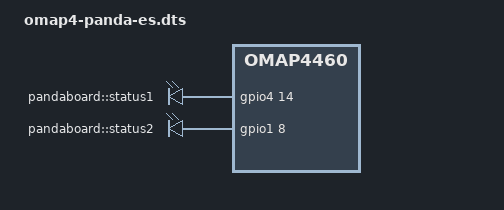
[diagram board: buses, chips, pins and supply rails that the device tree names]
/*
 * Copyright (C) 2012 Texas Instruments Incorporated - http://www.ti.com/
 *
 * This program is free software; you can redistribute it and/or modify
 * it under the terms of the GNU General Public License version 2 as
 * published by the Free Software Foundation.
 */
/dts-v1/;

/include/ "omap4460.dtsi"
/include/ "omap4-panda-common.dtsi"

&leds {
	compatible = "gpio-leds";
	heartbeat {
		label = "pandaboard::status1";
		gpios = <&gpio4 14 0>;
		linux,default-trigger = "heartbeat";
	};
	mmc {
		label = "pandaboard::status2";
		gpios = <&gpio1 8 0>;
		linux,default-trigger = "gpio";
	};
};

&led_gpio_pins {
	pinctrl-single,pins = <
		0xb6 0x3	/* gpio_110 OUTPUT | MODE 3 */
	>;
};

&omap4_pmx_wkup {
	pinctrl-names = "default";
	pinctrl-0 = <
		&led_wkgpio_pins
	>;

	led_wkgpio_pins: pinmux_leds_wkpins {
		pinctrl-single,pins = <
			0x1c 0x3	/* gpio_wk8 OUTPUT | MODE 3 */
		>;
	};
};

/* Audio routing is differnet between PandaBoard4430 and PandaBoardES */
&sound {
	ti,model = "PandaBoardES";

	/* Audio routing */
	ti,audio-routing =
		"Headset Stereophone", "HSOL",
		"Headset Stereophone", "HSOR",
		"Ext Spk", "HFL",
		"Ext Spk", "HFR",
		"Line Out", "AUXL",
		"Line Out", "AUXR",
		"AFML", "Line In",
		"AFMR", "Line In",
		"Headset Playback", "PDM_DL1",
		"Handsfree Playback", "PDM_DL2",
		"PDM_UL1", "Capture",
		"40122000.mcbsp Playback", "BT_VX_DL",
		"BT_VX_UL", "40122000.mcbsp Capture",
		"40124000.mcbsp Playback", "MM_EXT_DL",
		"MM_EXT_UL", "40124000.mcbsp Capture";
};

/* PandaboardES has external pullups on SCL & SDA */
&dss_hdmi_pins {
	pinctrl-single,pins = <
		0x5a 0x118	/* hdmi_cec.hdmi_cec INPUT PULLUP | MODE 0 */
		0x5c 0x100	/* hdmi_scl.hdmi_scl INPUT | MODE 0 */
		0x5e 0x100	/* hdmi_sda.hdmi_sda INPUT | MODE 0 */
		>;
};
